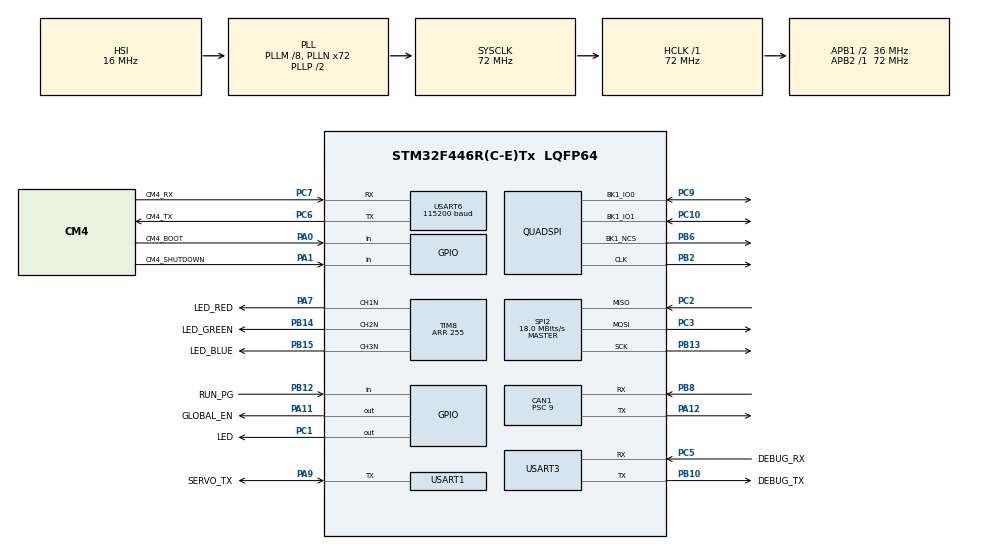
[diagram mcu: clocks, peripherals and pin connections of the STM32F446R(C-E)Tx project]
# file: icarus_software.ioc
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CAN1.BS1=CAN_BS1_13TQ
CAN1.BS2=CAN_BS2_2TQ
CAN1.CalculateBaudRate=250000
CAN1.CalculateTimeBit=4000
CAN1.CalculateTimeQuantum=250.0
CAN1.Prescaler=9
Dma.Request0=USART6_RX
Dma.Request1=USART3_RX
Dma.Request2=USART3_TX
Dma.Request3=USART6_TX
Dma.Request4=USART1_RX
Dma.Request5=USART1_TX
Dma.USART1_RX.4.Direction=DMA_PERIPH_TO_MEMORY
Dma.USART1_RX.4.FIFOMode=DMA_FIFOMODE_DISABLE
Dma.USART1_RX.4.Instance=DMA2_Stream5
Dma.USART1_RX.4.MemDataAlignment=DMA_MDATAALIGN_BYTE
Dma.USART1_RX.4.MemInc=DMA_MINC_ENABLE
Dma.USART1_RX.4.Mode=DMA_CIRCULAR
Dma.USART1_RX.4.PeriphDataAlignment=DMA_PDATAALIGN_BYTE
Dma.USART1_RX.4.PeriphInc=DMA_PINC_DISABLE
Dma.USART1_RX.4.Priority=DMA_PRIORITY_VERY_HIGH
Dma.USART1_TX.5.Direction=DMA_MEMORY_TO_PERIPH
Dma.USART1_TX.5.FIFOMode=DMA_FIFOMODE_DISABLE
Dma.USART1_TX.5.Instance=DMA2_Stream7
Dma.USART1_TX.5.MemDataAlignment=DMA_MDATAALIGN_BYTE
Dma.USART1_TX.5.MemInc=DMA_MINC_ENABLE
Dma.USART1_TX.5.Mode=DMA_NORMAL
Dma.USART1_TX.5.PeriphDataAlignment=DMA_PDATAALIGN_BYTE
Dma.USART1_TX.5.PeriphInc=DMA_PINC_DISABLE
Dma.USART1_TX.5.Priority=DMA_PRIORITY_HIGH
Dma.USART3_RX.1.Direction=DMA_PERIPH_TO_MEMORY
Dma.USART3_RX.1.FIFOMode=DMA_FIFOMODE_DISABLE
Dma.USART3_RX.1.Instance=DMA1_Stream1
Dma.USART3_RX.1.MemDataAlignment=DMA_MDATAALIGN_BYTE
Dma.USART3_RX.1.MemInc=DMA_MINC_ENABLE
Dma.USART3_RX.1.Mode=DMA_CIRCULAR
Dma.USART3_RX.1.PeriphDataAlignment=DMA_PDATAALIGN_BYTE
Dma.USART3_RX.1.PeriphInc=DMA_PINC_DISABLE
Dma.USART3_RX.1.Priority=DMA_PRIORITY_HIGH
Dma.USART3_TX.2.Direction=DMA_MEMORY_TO_PERIPH
Dma.USART3_TX.2.FIFOMode=DMA_FIFOMODE_DISABLE
Dma.USART3_TX.2.Instance=DMA1_Stream3
Dma.USART3_TX.2.MemDataAlignment=DMA_MDATAALIGN_BYTE
Dma.USART3_TX.2.MemInc=DMA_MINC_ENABLE
Dma.USART3_TX.2.Mode=DMA_NORMAL
Dma.USART3_TX.2.PeriphDataAlignment=DMA_PDATAALIGN_BYTE
Dma.USART3_TX.2.PeriphInc=DMA_PINC_DISABLE
Dma.USART3_TX.2.Priority=DMA_PRIORITY_MEDIUM
Dma.USART6_RX.0.Direction=DMA_PERIPH_TO_MEMORY
Dma.USART6_RX.0.FIFOMode=DMA_FIFOMODE_DISABLE
Dma.USART6_RX.0.Instance=DMA2_Stream2
Dma.USART6_RX.0.MemDataAlignment=DMA_MDATAALIGN_BYTE
Dma.USART6_RX.0.MemInc=DMA_MINC_ENABLE
Dma.USART6_RX.0.Mode=DMA_CIRCULAR
Dma.USART6_RX.0.PeriphDataAlignment=DMA_PDATAALIGN_BYTE
Dma.USART6_RX.0.PeriphInc=DMA_PINC_DISABLE
Dma.USART6_RX.0.Priority=DMA_PRIORITY_VERY_HIGH
Dma.USART6_TX.3.Direction=DMA_MEMORY_TO_PERIPH
Dma.USART6_TX.3.FIFOMode=DMA_FIFOMODE_DISABLE
Dma.USART6_TX.3.Instance=DMA2_Stream6
Dma.USART6_TX.3.MemDataAlignment=DMA_MDATAALIGN_BYTE
Dma.USART6_TX.3.MemInc=DMA_MINC_ENABLE
Dma.USART6_TX.3.Mode=DMA_NORMAL
Dma.USART6_TX.3.PeriphDataAlignment=DMA_PDATAALIGN_BYTE
Dma.USART6_TX.3.PeriphInc=DMA_PINC_DISABLE
Dma.USART6_TX.3.Priority=DMA_PRIORITY_HIGH
FREERTOS.INCLUDE_vTaskDelayUntil=1
FREERTOS.MEMORY_ALLOCATION=1
FREERTOS.Tasks01=defaultTask,0,128,StartDefaultTask,Default,NULL,Static,defaultTaskBuffer,defaultTaskControlBlock
FREERTOS.configCHECK_FOR_STACK_OVERFLOW=0
FREERTOS.configENABLE_FPU=1
FREERTOS.configGENERATE_RUN_TIME_STATS=1
FREERTOS.configUSE_STATS_FORMATTING_FUNCTIONS=0
FREERTOS.configUSE_TRACE_FACILITY=0
Mcu.Family=STM32F4
Mcu.Name=STM32F446R(C-E)Tx
Mcu.Package=LQFP64
NVIC.CAN1_RX0_IRQn=true\:5\:0\:true\:false\:true\:false\:true\:true
NVIC.DMA1_Stream1_IRQn=true\:5\:0\:true\:false\:true\:false\:false\:true
NVIC.DMA1_Stream3_IRQn=true\:5\:0\:true\:false\:true\:false\:false\:true
NVIC.DMA2_Stream2_IRQn=true\:5\:0\:true\:false\:true\:false\:false\:true
NVIC.DMA2_Stream5_IRQn=true\:5\:0\:false\:false\:true\:false\:false\:true
NVIC.DMA2_Stream6_IRQn=true\:5\:0\:true\:false\:true\:false\:false\:true
NVIC.DMA2_Stream7_IRQn=true\:5\:0\:true\:false\:true\:false\:false\:true
NVIC.PriorityGroup=NVIC_PRIORITYGROUP_4
NVIC.QUADSPI_IRQn=true\:5\:0\:true\:false\:true\:false\:true\:true
NVIC.TIM1_UP_TIM10_IRQn=true\:0\:0\:true\:false\:true\:false\:false\:true
NVIC.TimeBase=TIM1_UP_TIM10_IRQn
NVIC.TimeBaseIP=TIM1
NVIC.USART1_IRQn=true\:5\:0\:true\:false\:true\:false\:true\:true
NVIC.USART3_IRQn=true\:5\:0\:true\:false\:true\:false\:true\:true
NVIC.USART6_IRQn=true\:5\:0\:true\:false\:true\:false\:true\:true
PA0-WKUP.GPIO_Label=CM4_BOOT
PA0-WKUP.Signal=GPIO_Input
PA1.GPIO_Label=CM4_SHUTDOWN
PA1.Signal=GPIO_Input
PA11.GPIO_Label=GLOBAL_EN
PA11.GPIO_ModeDefaultOutputPP=GPIO_MODE_OUTPUT_OD
PA11.GPIO_Speed=GPIO_SPEED_FREQ_LOW
PA11.PinState=GPIO_PIN_RESET
PA11.Signal=GPIO_Output
PA12.Mode=CAN_Activate
PA12.Signal=CAN1_TX
PA2.Signal=S_TIM5_CH3
PA3.Signal=S_TIM5_CH4
PA7.GPIO_Label=LED_RED
PA7.Mode=PWM Generation1 CH1N
PA7.Signal=TIM8_CH1N
PA9.GPIO_Label=SERVO_TX
PA9.GPIO_ModeDefaultOD=GPIO_MODE_AF_OD
PA9.GPIO_PuPd=GPIO_PULLUP
PA9.Mode=Half_duplex(single_wire_mode)
PA9.Signal=USART1_TX
PB10.GPIO_Label=DEBUG_TX
PB10.Mode=Asynchronous
PB10.Signal=USART3_TX
PB12.GPIO_Label=RUN_PG
PB12.Signal=GPIO_Input
PB13.Mode=Full_Duplex_Master
PB13.Signal=SPI2_SCK
PB14.GPIO_Label=LED_GREEN
PB14.Mode=PWM Generation2 CH2N
PB14.Signal=TIM8_CH2N
PB15.GPIO_Label=LED_BLUE
PB15.Mode=PWM Generation3 CH3N
PB15.Signal=TIM8_CH3N
PB2.Mode=Single Bank 1 2IOs
PB2.Signal=QUADSPI_CLK
PB6.Mode=Single Bank 1 2IOs
PB6.Signal=QUADSPI_BK1_NCS
PB8.Mode=CAN_Activate
PB8.Signal=CAN1_RX
PC1.GPIO_Label=LED
PC1.Signal=GPIO_Output
PC10.Mode=Single Bank 1 2IOs
PC10.Signal=QUADSPI_BK1_IO1
PC2.Mode=Full_Duplex_Master
PC2.Signal=SPI2_MISO
PC3.Mode=Full_Duplex_Master
PC3.Signal=SPI2_MOSI
PC5.GPIO_Label=DEBUG_RX
PC5.Mode=Asynchronous
PC5.Signal=USART3_RX
PC6.GPIO_Label=CM4_TX
PC6.GPIO_ModeDefaultPP=GPIO_MODE_AF_PP
PC6.GPIO_PuPd=GPIO_NOPULL
PC6.Mode=Asynchronous
PC6.Signal=USART6_TX
PC7.GPIO_Label=CM4_RX
PC7.Mode=Asynchronous
PC7.Signal=USART6_RX
PC9.Mode=Single Bank 1 2IOs
PC9.Signal=QUADSPI_BK1_IO0
ProjectManager.HeapSize=0x200
ProjectManager.StackSize=0x400
ProjectManager.TargetToolchain=STM32CubeIDE
QUADSPI.ClockPrescaler=100
QUADSPI.FlashSize=26
RCC.AHBFreq_Value=72000000
RCC.APB1CLKDivider=RCC_HCLK_DIV2
RCC.APB1Freq_Value=36000000
RCC.APB1TimFreq_Value=72000000
RCC.APB2Freq_Value=72000000
RCC.APB2TimFreq_Value=72000000
RCC.CortexFreq_Value=72000000
RCC.HCLKFreq_Value=72000000
RCC.PLLM=8
RCC.PLLN=72
RCC.PLLQ=3
RCC.SYSCLKFreq_VALUE=72000000
RCC.SYSCLKSource=RCC_SYSCLKSOURCE_PLLCLK
RCC.USBFreq_Value=48000000
RCC.VCOOutputFreq_Value=144000000
SH.S_TIM5_CH3.0=TIM5_CH3
SH.S_TIM5_CH4.0=TIM5_CH4
SPI2.BaudRatePrescaler=SPI_BAUDRATEPRESCALER_2
SPI2.CRCCalculation=SPI_CRCCALCULATION_DISABLE
SPI2.CalculateBaudRate=18.0 MBits/s
SPI2.DataSize=SPI_DATASIZE_8BIT
SPI2.Direction=SPI_DIRECTION_2LINES
SPI2.Mode=SPI_MODE_MASTER
SPI2.VirtualType=VM_MASTER
TIM2.AutoReloadPreload=TIM_AUTORELOAD_PRELOAD_DISABLE
TIM2.CounterMode=TIM_COUNTERMODE_DOWN
TIM2.Period=1000
TIM2.Prescaler=49
TIM2.TIM_MasterOutputTrigger=TIM_TRGO_RESET
TIM3.CounterMode=TIM_COUNTERMODE_UP
TIM3.Period=1125
TIM3.Prescaler=0
TIM3.TIM_MasterOutputTrigger=TIM_TRGO_UPDATE
TIM3.TIM_MasterSlaveMode=TIM_MASTERSLAVEMODE_DISABLE
TIM5.Prescaler=7199
TIM8.AutoReloadPreload=TIM_AUTORELOAD_PRELOAD_DISABLE
TIM8.Channel-PWM\ Generation1\ CH1N=TIM_CHANNEL_1
TIM8.Channel-PWM\ Generation2\ CH2N=TIM_CHANNEL_2
TIM8.Channel-PWM\ Generation3\ CH3N=TIM_CHANNEL_3
TIM8.CounterMode=TIM_COUNTERMODE_UP
TIM8.OCNPolarity_1=TIM_OCNPOLARITY_LOW
TIM8.OCNPolarity_2=TIM_OCNPOLARITY_LOW
TIM8.OCNPolarity_3=TIM_OCNPOLARITY_LOW
TIM8.Period=255
TIM8.Pulse-PWM\ Generation1\ CH1N=128
TIM8.Pulse-PWM\ Generation2\ CH2N=128
USART1.BaudRate=115200
USART1.VirtualMode=VM_ASYNC
USART3.VirtualMode=VM_ASYNC
USART6.BaudRate=115200
USART6.OverSampling=UART_OVERSAMPLING_16
USART6.VirtualMode=VM_ASYNC
VP_FREERTOS_VS_CMSIS_V1.Mode=CMSIS_V1
VP_SYS_VS_tim1.Mode=TIM1
VP_TIM2_VS_ClockSourceINT.Mode=Internal
VP_TIM3_VS_ClockSourceINT.Mode=Internal
VP_TIM5_VS_ClockSourceINT.Mode=Internal
VP_TIM8_VS_ClockSourceINT.Mode=Internal
board=custom

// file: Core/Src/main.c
/* USER CODE BEGIN Header */
/**
  ******************************************************************************
  * @file           : main.c
  * @brief          : Main program body
  ******************************************************************************
  * @attention
  *
  * <h2><center>&copy; Copyright (c) 2020 STMicroelectronics.
  * All rights reserved.</center></h2>
  *
  * This software component is licensed by ST under BSD 3-Clause license,
  * the "License"; You may not use this file except in compliance with the
  * License. You may obtain a copy of the License at:
  *                        opensource.org/licenses/BSD-3-Clause
  *
  ******************************************************************************
  */
/* USER CODE END Header */
#include "main.h"
#include "cmsis_os.h"
#include "can.h"
#include "dma.h"
#include "iwdg.h"
#include "quadspi.h"
#include "spi.h"
#include "tim.h"
#include "usart.h"
#include "gpio.h"

/* USER CODE BEGIN Includes */
#include <threads.h>
#include <led.h>
#include <cmsis_os.h>

/* USER CODE END Includes */

void SystemClock_Config(void);
void MX_FREERTOS_Init(void);

int main(void)
{

  /* MCU Configuration--------------------------------------------------------*/

  /* Reset of all peripherals, Initializes the Flash interface and the Systick. */
  HAL_Init();

  /* Configure the system clock */
  SystemClock_Config();

  /* Initialize all configured peripherals */
  MX_GPIO_Init();
  MX_DMA_Init();
  MX_TIM8_Init();
  MX_TIM2_Init();
  MX_USART6_UART_Init();
  MX_USART3_UART_Init();
  MX_QUADSPI_Init();
  MX_TIM3_Init();
  MX_CAN1_Init();
  MX_USART1_UART_Init();
  MX_TIM5_Init();
  MX_SPI2_Init();
  MX_IWDG_Init();
  /* USER CODE BEGIN 2 */

  threads_init();

  /* USER CODE END 2 */

  /* Call init function for freertos objects (in freertos.c) */
  MX_FREERTOS_Init();
  /* Start scheduler */
  osKernelStart();

  /* We should never get here as control is now taken by the scheduler */
  /* Infinite loop */
  /* USER CODE BEGIN WHILE */

  while (1)
  {
	osDelay(1000);
    /* USER CODE END WHILE */

  }
}

void SystemClock_Config(void)
{
  RCC_OscInitTypeDef RCC_OscInitStruct = {0};
  RCC_ClkInitTypeDef RCC_ClkInitStruct = {0};

  /** Configure the main internal regulator output voltage
  */
  __HAL_RCC_PWR_CLK_ENABLE();
  __HAL_PWR_VOLTAGESCALING_CONFIG(PWR_REGULATOR_VOLTAGE_SCALE3);
  /** Initializes the RCC Oscillators according to the specified parameters
  * in the RCC_OscInitTypeDef structure.
  */
  RCC_OscInitStruct.OscillatorType = RCC_OSCILLATORTYPE_HSI|RCC_OSCILLATORTYPE_LSI;
  RCC_OscInitStruct.HSIState = RCC_HSI_ON;
  RCC_OscInitStruct.HSICalibrationValue = RCC_HSICALIBRATION_DEFAULT;
  RCC_OscInitStruct.LSIState = RCC_LSI_ON;
  RCC_OscInitStruct.PLL.PLLState = RCC_PLL_ON;
  RCC_OscInitStruct.PLL.PLLSource = RCC_PLLSOURCE_HSI;
  RCC_OscInitStruct.PLL.PLLM = 8;
  RCC_OscInitStruct.PLL.PLLN = 72;
  RCC_OscInitStruct.PLL.PLLP = RCC_PLLP_DIV2;
  RCC_OscInitStruct.PLL.PLLQ = 3;
  RCC_OscInitStruct.PLL.PLLR = 2;
  if (HAL_RCC_OscConfig(&RCC_OscInitStruct) != HAL_OK)
  {
    Error_Handler();
  }
  /** Initializes the CPU, AHB and APB buses clocks
  */
  RCC_ClkInitStruct.ClockType = RCC_CLOCKTYPE_HCLK|RCC_CLOCKTYPE_SYSCLK
                              |RCC_CLOCKTYPE_PCLK1|RCC_CLOCKTYPE_PCLK2;
  RCC_ClkInitStruct.SYSCLKSource = RCC_SYSCLKSOURCE_PLLCLK;
  RCC_ClkInitStruct.AHBCLKDivider = RCC_SYSCLK_DIV1;
  RCC_ClkInitStruct.APB1CLKDivider = RCC_HCLK_DIV2;
  RCC_ClkInitStruct.APB2CLKDivider = RCC_HCLK_DIV1;

  if (HAL_RCC_ClockConfig(&RCC_ClkInitStruct, FLASH_LATENCY_2) != HAL_OK)
  {
    Error_Handler();
  }
}

 /**
  * @brief  Period elapsed callback in non blocking mode
  * @note   This function is called  when TIM1 interrupt took place, inside
  * HAL_TIM_IRQHandler(). It makes a direct call to HAL_IncTick() to increment
  * a global variable "uwTick" used as application time base.
  * @param  htim : TIM handle
  * @retval None
  */
void HAL_TIM_PeriodElapsedCallback(TIM_HandleTypeDef *htim)
{
  if (htim->Instance == TIM1) {
    HAL_IncTick();
  }
}

void Error_Handler(void)
{
}

/************************ (C) COPYRIGHT STMicroelectronics *****END OF FILE****/

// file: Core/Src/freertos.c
/* USER CODE BEGIN Header */
/**
  ******************************************************************************
  * File Name          : freertos.c
  * Description        : Code for freertos applications
  ******************************************************************************
  * @attention
  *
  * <h2><center>&copy; Copyright (c) 2021 STMicroelectronics.
  * All rights reserved.</center></h2>
  *
  * This software component is licensed by ST under Ultimate Liberty license
  * SLA0044, the "License"; You may not use this file except in compliance with
  * the License. You may obtain a copy of the License at:
  *                             www.st.com/SLA0044
  *
  ******************************************************************************
  */
/* USER CODE END Header */

#include "FreeRTOS.h"
#include "task.h"
#include "main.h"
#include "cmsis_os.h"

osThreadId defaultTaskHandle;
uint32_t defaultTaskBuffer[ 128 ];
osStaticThreadDef_t defaultTaskControlBlock;

void StartDefaultTask(void const * argument);

void MX_FREERTOS_Init(void); /* (MISRA C 2004 rule 8.1) */

/* GetIdleTaskMemory prototype (linked to static allocation support) */
void vApplicationGetIdleTaskMemory( StaticTask_t **ppxIdleTaskTCBBuffer, StackType_t **ppxIdleTaskStackBuffer, uint32_t *pulIdleTaskStackSize );

/* Hook prototypes */
void configureTimerForRunTimeStats(void);
unsigned long getRunTimeCounterValue(void);

/* USER CODE BEGIN 1 */
/* Functions needed when configGENERATE_RUN_TIME_STATS is on */
__weak void configureTimerForRunTimeStats(void)
{
	TIM5->CR1 = 0b1;
}

__weak unsigned long getRunTimeCounterValue(void)
{
return TIM5->CNT;
}
/* USER CODE END 1 */

/* USER CODE BEGIN GET_IDLE_TASK_MEMORY */
static StaticTask_t xIdleTaskTCBBuffer;
static StackType_t xIdleStack[configMINIMAL_STACK_SIZE];

void vApplicationGetIdleTaskMemory( StaticTask_t **ppxIdleTaskTCBBuffer, StackType_t **ppxIdleTaskStackBuffer, uint32_t *pulIdleTaskStackSize )
{
  *ppxIdleTaskTCBBuffer = &xIdleTaskTCBBuffer;
  *ppxIdleTaskStackBuffer = &xIdleStack[0];
  *pulIdleTaskStackSize = configMINIMAL_STACK_SIZE;
  /* place for user code */
}
/* USER CODE END GET_IDLE_TASK_MEMORY */

void MX_FREERTOS_Init(void) {

  /* Create the thread(s) */
  /* definition and creation of defaultTask */
  osThreadStaticDef(defaultTask, StartDefaultTask, osPriorityNormal, 0, 128, defaultTaskBuffer, &defaultTaskControlBlock);
  defaultTaskHandle = osThreadCreate(osThread(defaultTask), NULL);

}

void StartDefaultTask(void const * argument)
{
  for(;;)
  {
    osDelay(1);
  }
}

/************************ (C) COPYRIGHT STMicroelectronics *****END OF FILE****/
